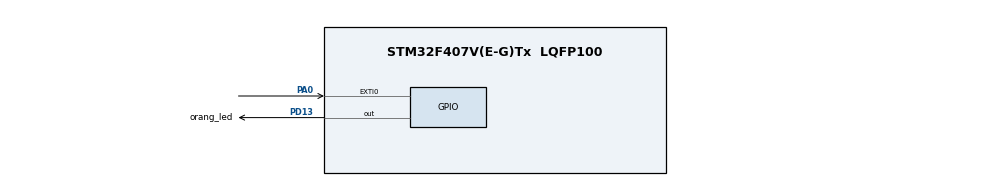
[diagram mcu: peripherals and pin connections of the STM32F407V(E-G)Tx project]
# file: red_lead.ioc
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Mcu.Family=STM32F4
Mcu.Name=STM32F407V(E-G)Tx
Mcu.Package=LQFP100
NVIC.EXTI0_IRQn=true\:0\:0
NVIC.PriorityGroup=NVIC_PRIORITYGROUP_0
NVIC.TIM7_IRQn=true\:0\:0
PA0-WKUP.GPIO_ModeDefaultEXTI=GPIO_MODE_IT_RISING_FALLING
PA0-WKUP.GPIO_PuPd=GPIO_NOPULL
PA0-WKUP.Signal=GPXTI0
PD13.GPIO_Label=orang_led
PD13.GPIO_ModeDefaultOutputPP=GPIO_MODE_OUTPUT_PP
PD13.GPIO_PuPd=GPIO_NOPULL
PD13.GPIO_Speed=GPIO_SPEED_FAST
PD13.Signal=GPIO_Output
ProjectManager.TargetToolchain=MDK-ARM 4.73
RCC.HSE_VALUE=25000000
RCC.HSI_VALUE=16000000
RCC.LSE_VALUE=32768
VP_TIM7_VS_ClockSourceINT.Mode=Enable_Timer

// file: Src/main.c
/**
  ******************************************************************************
  * File Name          : main.c
  * Date               : 03/12/2014 16:50:56
  * Description        : Main program body
  ******************************************************************************
  *
  * COPYRIGHT(c) 2014 STMicroelectronics
  *
  * Redistribution and use in source and binary forms, with or without modification,
  * are permitted provided that the following conditions are met:
  *   1. Redistributions of source code must retain the above copyright notice,
  *      this list of conditions and the following disclaimer.
  *   2. Redistributions in binary form must reproduce the above copyright notice,
  *      this list of conditions and the following disclaimer in the documentation
  *      and/or other materials provided with the distribution.
  *   3. Neither the name of STMicroelectronics nor the names of its contributors
  *      may be used to endorse or promote products derived from this software
  *      without specific prior written permission.
  *
  * THIS SOFTWARE IS PROVIDED BY THE COPYRIGHT HOLDERS AND CONTRIBUTORS "AS IS"
  * AND ANY EXPRESS OR IMPLIED WARRANTIES, INCLUDING, BUT NOT LIMITED TO, THE
  * IMPLIED WARRANTIES OF MERCHANTABILITY AND FITNESS FOR A PARTICULAR PURPOSE ARE
  * DISCLAIMED. IN NO EVENT SHALL THE COPYRIGHT HOLDER OR CONTRIBUTORS BE LIABLE
  * FOR ANY DIRECT, INDIRECT, INCIDENTAL, SPECIAL, EXEMPLARY, OR CONSEQUENTIAL
  * DAMAGES (INCLUDING, BUT NOT LIMITED TO, PROCUREMENT OF SUBSTITUTE GOODS OR
  * SERVICES; LOSS OF USE, DATA, OR PROFITS; OR BUSINESS INTERRUPTION) HOWEVER
  * CAUSED AND ON ANY THEORY OF LIABILITY, WHETHER IN CONTRACT, STRICT LIABILITY,
  * OR TORT (INCLUDING NEGLIGENCE OR OTHERWISE) ARISING IN ANY WAY OUT OF THE USE
  * OF THIS SOFTWARE, EVEN IF ADVISED OF THE POSSIBILITY OF SUCH DAMAGE.
  *
  ******************************************************************************
  */

#include "stm32f4xx_hal.h"
#include "tim.h"
#include "gpio.h"

/* USER CODE BEGIN 0 */
	void Delay(__IO uint32_t nCount)
	{
		while(nCount--)
		{
		}
	}

	GPIO_PinState pinState;
/* USER CODE END 0 */

void SystemClock_Config(void);

int main(void)
{

  /* MCU Configuration----------------------------------------------------------*/

  /* Reset of all peripherals, Initializes the Flash interface and the Systick. */
  HAL_Init();

  /* Configure the system clock */
  SystemClock_Config();

  /* System interrupt init*/
  /* Sets the priority grouping field */
  HAL_NVIC_SetPriorityGrouping(NVIC_PRIORITYGROUP_0);
  HAL_NVIC_SetPriority(SysTick_IRQn, 0, 0);

  /* Initialize all configured peripherals */
  MX_GPIO_Init();
  MX_TIM7_Init();

  /* USER CODE BEGIN 2 */

	HAL_GPIO_WritePin (  GPIOD, GPIO_PIN_13, GPIO_PIN_SET );
	Delay(0x3FFFFF);

  /* USER CODE END 2 */

  while (1)
  {
  }

}

/** System Clock Configuration
*/
void SystemClock_Config(void)
{

  RCC_OscInitTypeDef RCC_OscInitStruct;

  __PWR_CLK_ENABLE();

  __HAL_PWR_VOLTAGESCALING_CONFIG(PWR_REGULATOR_VOLTAGE_SCALE2);

  RCC_OscInitStruct.OscillatorType = RCC_OSCILLATORTYPE_HSI;
  RCC_OscInitStruct.HSIState = RCC_HSI_ON;
  RCC_OscInitStruct.HSICalibrationValue = 6;
  RCC_OscInitStruct.PLL.PLLState = RCC_PLL_NONE;
  HAL_RCC_OscConfig(&RCC_OscInitStruct);

}

/* USER CODE BEGIN 4 */
void HAL_GPIO_EXTI_Callback ( uint16_t GPIO_Pin )
{
	pinState =  HAL_GPIO_ReadPin ( GPIOA, GPIO_PIN_0);

	if( pinState == GPIO_PIN_SET)
	{
		HAL_GPIO_WritePin( GPIOD, GPIO_PIN_13, GPIO_PIN_SET );
	}
	else
	{
		HAL_GPIO_WritePin( GPIOD, GPIO_PIN_13, GPIO_PIN_RESET );
	}
}

/* USER CODE END 4 */

/************************ (C) COPYRIGHT STMicroelectronics *****END OF FILE****/
